# STM32G030C6T6 register map
File version: 1.0
Registers are 32-bit, access not given, reset 0x0 unless marked. A register's access mark holds for its fields unless they carry their own. Offsets are from the block's base; [hi:lo] are bit positions; {n}, {i} and the like mark numbered series.

## USB
Base 0x40005C00
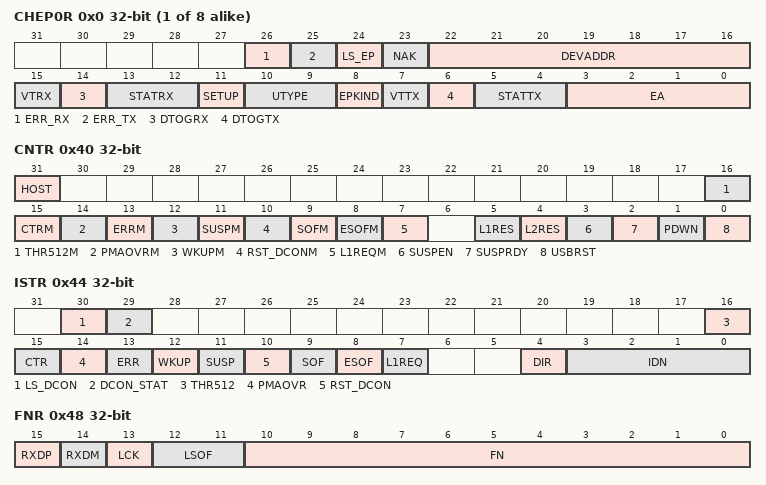
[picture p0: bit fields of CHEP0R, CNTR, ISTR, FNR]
{0x0+4i} CHEP{i}R (i=0..7)
  [26] ERR_RX, [25] ERR_TX, [24] LS_EP, [23] NAK, [22:16] DEVADDR, [15] VTRX, [14] DTOGRX, [13:12] STATRX, [11] SETUP, [10:9] UTYPE, [8] EPKIND, [7] VTTX, [6] DTOGTX, [5:4] STATTX, [3:0] EA
0x40 CNTR
  [31] HOST, [16] THR512M, [15] CTRM, [14] PMAOVRM, [13] ERRM, [12] WKUPM, [11] SUSPM, [10] RST_DCONM, [9] SOFM, [8] ESOFM, [7] L1REQM, [5] L1RES, [4] L2RES, [3] SUSPEN, [2] SUSPRDY, [1] PDWN, [0] USBRST
0x44 ISTR
  [30] LS_DCON, [29] DCON_STAT, [16] THR512, [15] CTR, [14] PMAOVR, [13] ERR, [12] WKUP, [11] SUSP, [10] RST_DCON, [9] SOF, [8] ESOF, [7] L1REQ, [4] DIR, [3:0] IDN
0x48 FNR
  [15] RXDP, [14] RXDM, [13] LCK, [12:11] LSOF, [10:0] FN
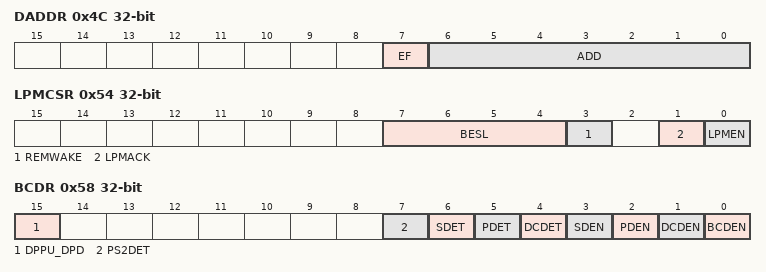
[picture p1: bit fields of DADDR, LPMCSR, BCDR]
0x4C DADDR
  [7] EF, [6:0] ADD
0x54 LPMCSR
  [7:4] BESL, [3] REMWAKE, [1] LPMACK, [0] LPMEN
0x58 BCDR
  [15] DPPU_DPD, [7] PS2DET, [6] SDET, [5] PDET, [4] DCDET, [3] SDEN, [2] PDEN, [1] DCDEN, [0] BCDEN

## PWR
Base 0x40007000
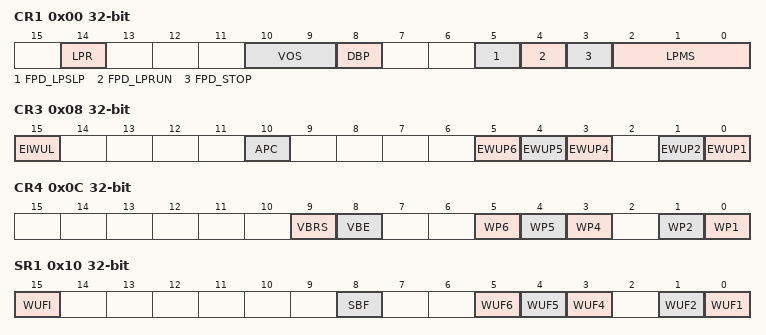
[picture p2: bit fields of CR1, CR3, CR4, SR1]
0x00 CR1
  [14] LPR, [10:9] VOS, [8] DBP, [5] FPD_LPSLP, [4] FPD_LPRUN, [3] FPD_STOP, [2:0] LPMS
0x04 CR2
  [10] USV
0x08 CR3
  [15] EIWUL, [10] APC, [5] EWUP6, [4] EWUP5, [3] EWUP4, [1] EWUP2, [0] EWUP1
0x0C CR4
  [9] VBRS, [8] VBE, [5] WP6, [4] WP5, [3] WP4, [1] WP2, [0] WP1
0x10 SR1
  [15] WUFI, [8] SBF, [5] WUF6, [4] WUF5, [3] WUF4, [1] WUF2, [0] WUF1
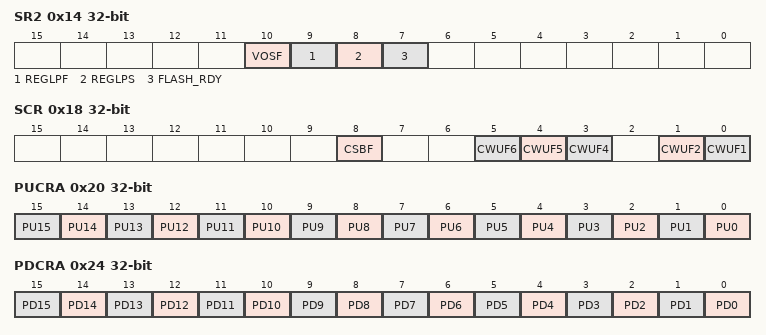
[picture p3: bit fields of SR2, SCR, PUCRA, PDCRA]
0x14 SR2
  [10] VOSF, [9] REGLPF, [8] REGLPS, [7] FLASH_RDY
0x18 SCR
  [8] CSBF, [5] CWUF6, [4] CWUF5, [3] CWUF4, [1] CWUF2, [0] CWUF1
0x20 PUCRA
  [n] PU{n} (n=0..15)
0x24 PDCRA
  [n] PD{n} (n=0..15)
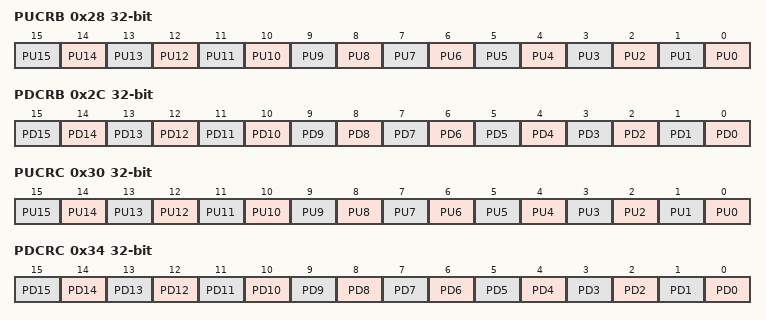
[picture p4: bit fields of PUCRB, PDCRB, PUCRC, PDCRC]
0x28 PUCRB
  [n] PU{n} (n=0..15)
0x2C PDCRB
  [n] PD{n} (n=0..15)
0x30 PUCRC
  [n] PU{n} (n=0..15)
0x34 PDCRC
  [n] PD{n} (n=0..15)
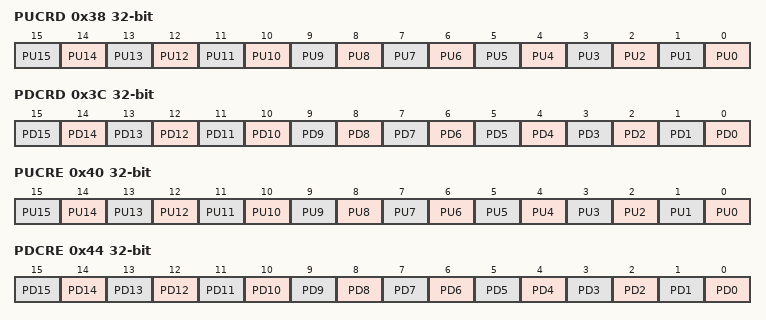
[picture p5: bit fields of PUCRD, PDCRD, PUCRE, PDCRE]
0x38 PUCRD
  [n] PU{n} (n=0..15)
0x3C PDCRD
  [n] PD{n} (n=0..15)
0x40 PUCRE
  [n] PU{n} (n=0..15)
0x44 PDCRE
  [n] PD{n} (n=0..15)
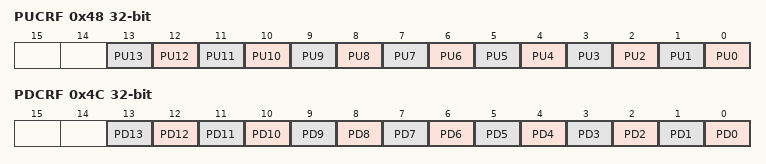
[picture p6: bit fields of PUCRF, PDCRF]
0x48 PUCRF
  [n] PU{n} (n=0..13)
0x4C PDCRF
  [n] PD{n} (n=0..13)

## TAMP
Base 0x4000B000
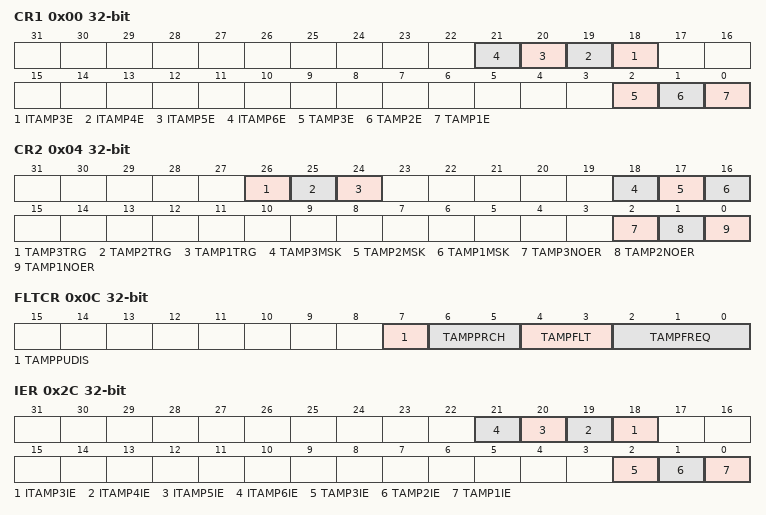
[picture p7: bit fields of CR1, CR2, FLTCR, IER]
0x00 CR1
  [n+15] ITAMP{n}E (n=3..6), [2] TAMP3E, [1] TAMP2E, [0] TAMP1E
0x04 CR2
  [26] TAMP3TRG, [25] TAMP2TRG, [24] TAMP1TRG, [18] TAMP3MSK, [17] TAMP2MSK, [16] TAMP1MSK, [2] TAMP3NOER, [1] TAMP2NOER, [0] TAMP1NOER
0x0C FLTCR
  [7] TAMPPUDIS, [6:5] TAMPPRCH, [4:3] TAMPFLT, [2:0] TAMPFREQ
0x2C IER
  [n+15] ITAMP{n}IE (n=3..6), [2] TAMP3IE, [1] TAMP2IE, [0] TAMP1IE
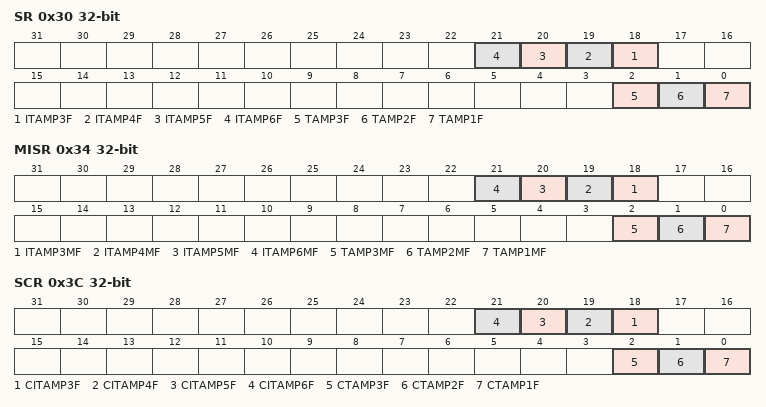
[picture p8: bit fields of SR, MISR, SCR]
0x30 SR
  [n+15] ITAMP{n}F (n=3..6), [2] TAMP3F, [1] TAMP2F, [0] TAMP1F
0x34 MISR
  [n+15] ITAMP{n}MF (n=3..6), [2] TAMP3MF, [1] TAMP2MF, [0] TAMP1MF
0x3C SCR
  [n+15] CITAMP{n}F (n=3..6), [2] CTAMP3F, [1] CTAMP2F, [0] CTAMP1F
{0x100+4i} BKP{i}R (i=0..4)
  [31:0] BKP

## SYSCFG
Base 0x40010000
Same registers: ITLINE 0x40010080
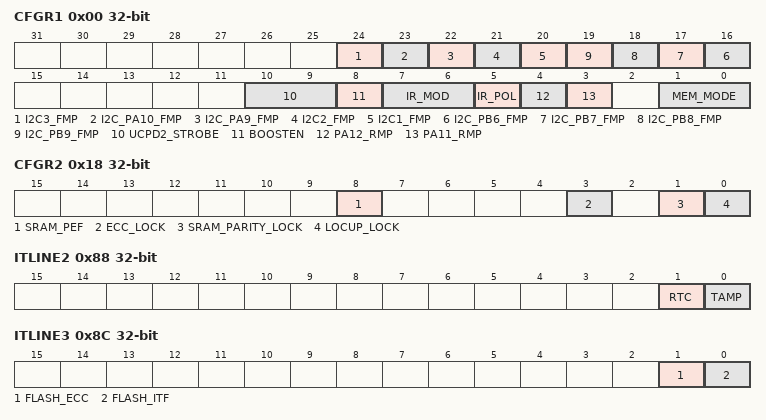
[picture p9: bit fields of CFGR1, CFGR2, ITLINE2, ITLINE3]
0x00 CFGR1
  [24] I2C3_FMP, [23] I2C_PA10_FMP, [22] I2C_PA9_FMP, [21] I2C2_FMP, [20] I2C1_FMP, [n+10] I2C_PB{n}_FMP (n=6..9), [10:9] UCPD2_STROBE, [8] BOOSTEN, [7:6] IR_MOD, [5] IR_POL, [4] PA12_RMP, [3] PA11_RMP, [1:0] MEM_MODE
0x18 CFGR2
  [8] SRAM_PEF, [3] ECC_LOCK, [1] SRAM_PARITY_LOCK, [0] LOCUP_LOCK
0x80 ITLINE0
  [0] WWDG
0x88 ITLINE2
  [1] RTC, [0] TAMP
0x8C ITLINE3
  [1] FLASH_ECC, [0] FLASH_ITF
0x90 ITLINE4
  [0] RCC
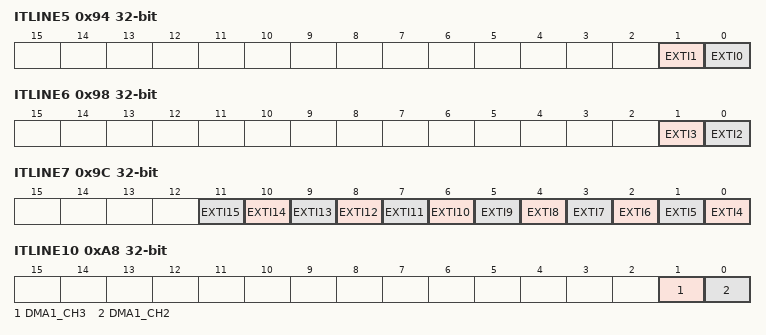
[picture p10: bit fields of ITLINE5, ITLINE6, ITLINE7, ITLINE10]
0x94 ITLINE5
  [1] EXTI1, [0] EXTI0
0x98 ITLINE6
  [1] EXTI3, [0] EXTI2
0x9C ITLINE7
  [n-4] EXTI{n} (n=4..15)
0xA0 ITLINE8
  [2] USB
0xA4 ITLINE9
  [0] DMA1_CH1
0xA8 ITLINE10
  [1] DMA1_CH3, [0] DMA1_CH2
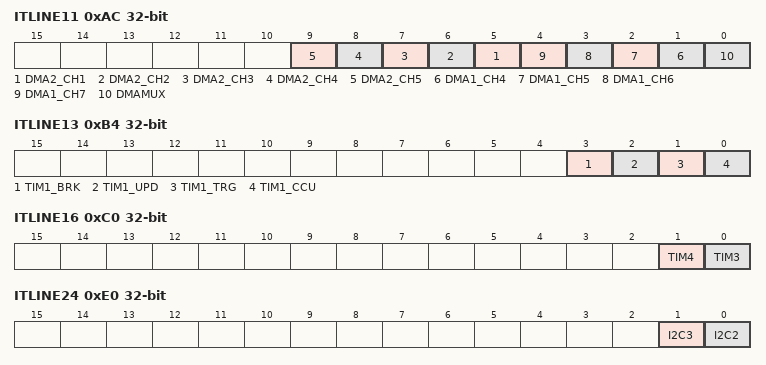
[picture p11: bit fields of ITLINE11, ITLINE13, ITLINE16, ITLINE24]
0xAC ITLINE11
  [n+4] DMA2_CH{n} (n=1..5), [n-3] DMA1_CH{n} (n=4..7), [0] DMAMUX
0xB0 ITLINE12
  [0] ADC
0xB4 ITLINE13
  [3] TIM1_BRK, [2] TIM1_UPD, [1] TIM1_TRG, [0] TIM1_CCU
0xB8 ITLINE14
  [0] TIM1_CC
0xC0 ITLINE16
  [1] TIM4, [0] TIM3
0xC4 ITLINE17
  [0] TIM6
0xC8 ITLINE18
  [0] TIM7
{0x80+4i} ITLINE{i} (i=19..22)
  [0] TIM{i-5}
0xDC ITLINE23
  [0] I2C1
0xE0 ITLINE24
  [1] I2C3, [0] I2C2
0xE4 ITLINE25
  [0] SPI1
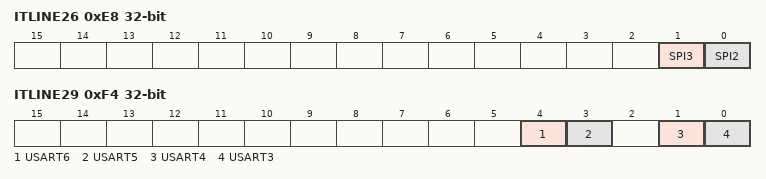
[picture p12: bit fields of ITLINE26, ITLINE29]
0xE8 ITLINE26
  [1] SPI3, [0] SPI2
0xEC ITLINE27
  [0] USART1
0xF0 ITLINE28
  [0] USART2
0xF4 ITLINE29
  [4] USART6, [3] USART5, [1] USART4, [0] USART3
